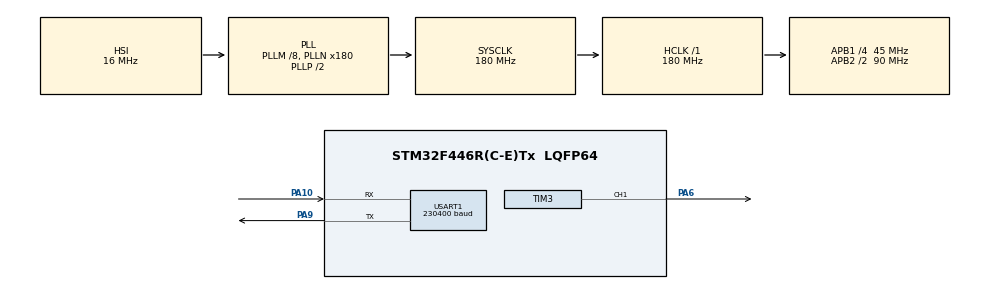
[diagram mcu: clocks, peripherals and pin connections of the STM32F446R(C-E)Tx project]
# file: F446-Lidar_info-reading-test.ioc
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Dma.Request0=USART1_RX
Dma.USART1_RX.0.Direction=DMA_PERIPH_TO_MEMORY
Dma.USART1_RX.0.FIFOMode=DMA_FIFOMODE_DISABLE
Dma.USART1_RX.0.Instance=DMA2_Stream2
Dma.USART1_RX.0.MemDataAlignment=DMA_MDATAALIGN_BYTE
Dma.USART1_RX.0.MemInc=DMA_MINC_ENABLE
Dma.USART1_RX.0.Mode=DMA_CIRCULAR
Dma.USART1_RX.0.PeriphDataAlignment=DMA_PDATAALIGN_BYTE
Dma.USART1_RX.0.PeriphInc=DMA_PINC_DISABLE
Dma.USART1_RX.0.Priority=DMA_PRIORITY_MEDIUM
Mcu.Family=STM32F4
Mcu.Name=STM32F446R(C-E)Tx
Mcu.Package=LQFP64
NVIC.DMA2_Stream2_IRQn=true\:0\:0\:false\:false\:true\:false\:true\:true
NVIC.PriorityGroup=NVIC_PRIORITYGROUP_4
PA10.Mode=Asynchronous
PA10.Signal=USART1_RX
PA6.Signal=S_TIM3_CH1
PA9.Mode=Asynchronous
PA9.Signal=USART1_TX
ProjectManager.HeapSize=0x200
ProjectManager.StackSize=0x400
ProjectManager.TargetToolchain=STM32CubeIDE
RCC.AHBFreq_Value=180000000
RCC.APB1CLKDivider=RCC_HCLK_DIV4
RCC.APB1Freq_Value=45000000
RCC.APB1TimFreq_Value=90000000
RCC.APB2CLKDivider=RCC_HCLK_DIV2
RCC.APB2Freq_Value=90000000
RCC.APB2TimFreq_Value=180000000
RCC.CortexFreq_Value=180000000
RCC.HCLKFreq_Value=180000000
RCC.PLLM=8
RCC.PLLN=180
RCC.SYSCLKFreq_VALUE=180000000
RCC.SYSCLKSource=RCC_SYSCLKSOURCE_PLLCLK
RCC.USBFreq_Value=180000000
RCC.VCOOutputFreq_Value=360000000
SH.S_TIM3_CH1.0=TIM3_CH1,PWM Generation1 CH1
TIM3.Channel-PWM\ Generation1\ CH1=TIM_CHANNEL_1
TIM3.Period=1000-1
TIM3.Prescaler=30-1
USART1.BaudRate=230400
USART1.VirtualMode=VM_ASYNC
board=custom

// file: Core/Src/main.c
/* USER CODE BEGIN Header */
/**
  ******************************************************************************
  * @file           : main.c
  * @brief          : Main program body
  ******************************************************************************
  * @attention
  *
  * Copyright (c) 2025 STMicroelectronics.
  * All rights reserved.
  *
  * This software is licensed under terms that can be found in the LICENSE file
  * in the root directory of this software component.
  * If no LICENSE file comes with this software, it is provided AS-IS.
  *
  ******************************************************************************
  */
/* USER CODE END Header */
#include "main.h"

/* USER CODE BEGIN Includes */
#include "mainpp.hpp"
/* USER CODE END Includes */

TIM_HandleTypeDef htim3;

UART_HandleTypeDef huart1;
DMA_HandleTypeDef hdma_usart1_rx;

void SystemClock_Config(void);
static void MX_GPIO_Init(void);
static void MX_DMA_Init(void);
static void MX_USART1_UART_Init(void);
static void MX_TIM3_Init(void);

int main(void)
{

  /* MCU Configuration--------------------------------------------------------*/

  /* Reset of all peripherals, Initializes the Flash interface and the Systick. */
  HAL_Init();

  /* Configure the system clock */
  SystemClock_Config();

  /* Initialize all configured peripherals */
  MX_GPIO_Init();
  MX_DMA_Init();
  MX_USART1_UART_Init();
  MX_TIM3_Init();
  /* USER CODE BEGIN 2 */
  main_function();
  /* USER CODE END 2 */

  /* Infinite loop */
  while (1)
  {

  }
}

void SystemClock_Config(void)
{
  RCC_OscInitTypeDef RCC_OscInitStruct = {0};
  RCC_ClkInitTypeDef RCC_ClkInitStruct = {0};

  /** Configure the main internal regulator output voltage
  */
  __HAL_RCC_PWR_CLK_ENABLE();
  __HAL_PWR_VOLTAGESCALING_CONFIG(PWR_REGULATOR_VOLTAGE_SCALE1);

  /** Initializes the RCC Oscillators according to the specified parameters
  * in the RCC_OscInitTypeDef structure.
  */
  RCC_OscInitStruct.OscillatorType = RCC_OSCILLATORTYPE_HSI;
  RCC_OscInitStruct.HSIState = RCC_HSI_ON;
  RCC_OscInitStruct.HSICalibrationValue = RCC_HSICALIBRATION_DEFAULT;
  RCC_OscInitStruct.PLL.PLLState = RCC_PLL_ON;
  RCC_OscInitStruct.PLL.PLLSource = RCC_PLLSOURCE_HSI;
  RCC_OscInitStruct.PLL.PLLM = 8;
  RCC_OscInitStruct.PLL.PLLN = 180;
  RCC_OscInitStruct.PLL.PLLP = RCC_PLLP_DIV2;
  RCC_OscInitStruct.PLL.PLLQ = 2;
  RCC_OscInitStruct.PLL.PLLR = 2;
  if (HAL_RCC_OscConfig(&RCC_OscInitStruct) != HAL_OK)
  {
    Error_Handler();
  }

  /** Activate the Over-Drive mode
  */
  if (HAL_PWREx_EnableOverDrive() != HAL_OK)
  {
    Error_Handler();
  }

  /** Initializes the CPU, AHB and APB buses clocks
  */
  RCC_ClkInitStruct.ClockType = RCC_CLOCKTYPE_HCLK|RCC_CLOCKTYPE_SYSCLK
                              |RCC_CLOCKTYPE_PCLK1|RCC_CLOCKTYPE_PCLK2;
  RCC_ClkInitStruct.SYSCLKSource = RCC_SYSCLKSOURCE_PLLCLK;
  RCC_ClkInitStruct.AHBCLKDivider = RCC_SYSCLK_DIV1;
  RCC_ClkInitStruct.APB1CLKDivider = RCC_HCLK_DIV4;
  RCC_ClkInitStruct.APB2CLKDivider = RCC_HCLK_DIV2;

  if (HAL_RCC_ClockConfig(&RCC_ClkInitStruct, FLASH_LATENCY_5) != HAL_OK)
  {
    Error_Handler();
  }
}

static void MX_TIM3_Init(void)
{

  TIM_MasterConfigTypeDef sMasterConfig = {0};
  TIM_OC_InitTypeDef sConfigOC = {0};

  htim3.Instance = TIM3;
  htim3.Init.Prescaler = 30-1;
  htim3.Init.CounterMode = TIM_COUNTERMODE_UP;
  htim3.Init.Period = 1000-1;
  htim3.Init.ClockDivision = TIM_CLOCKDIVISION_DIV1;
  htim3.Init.AutoReloadPreload = TIM_AUTORELOAD_PRELOAD_DISABLE;
  if (HAL_TIM_PWM_Init(&htim3) != HAL_OK)
  {
    Error_Handler();
  }
  sMasterConfig.MasterOutputTrigger = TIM_TRGO_RESET;
  sMasterConfig.MasterSlaveMode = TIM_MASTERSLAVEMODE_DISABLE;
  if (HAL_TIMEx_MasterConfigSynchronization(&htim3, &sMasterConfig) != HAL_OK)
  {
    Error_Handler();
  }
  sConfigOC.OCMode = TIM_OCMODE_PWM1;
  sConfigOC.Pulse = 0;
  sConfigOC.OCPolarity = TIM_OCPOLARITY_HIGH;
  sConfigOC.OCFastMode = TIM_OCFAST_DISABLE;
  if (HAL_TIM_PWM_ConfigChannel(&htim3, &sConfigOC, TIM_CHANNEL_1) != HAL_OK)
  {
    Error_Handler();
  }
  HAL_TIM_MspPostInit(&htim3);

}

static void MX_USART1_UART_Init(void)
{

  huart1.Instance = USART1;
  huart1.Init.BaudRate = 230400;
  huart1.Init.WordLength = UART_WORDLENGTH_8B;
  huart1.Init.StopBits = UART_STOPBITS_1;
  huart1.Init.Parity = UART_PARITY_NONE;
  huart1.Init.Mode = UART_MODE_TX_RX;
  huart1.Init.HwFlowCtl = UART_HWCONTROL_NONE;
  huart1.Init.OverSampling = UART_OVERSAMPLING_16;
  if (HAL_UART_Init(&huart1) != HAL_OK)
  {
    Error_Handler();
  }

}

static void MX_DMA_Init(void)
{

  /* DMA controller clock enable */
  __HAL_RCC_DMA2_CLK_ENABLE();

  /* DMA interrupt init */
  /* DMA2_Stream2_IRQn interrupt configuration */
  HAL_NVIC_SetPriority(DMA2_Stream2_IRQn, 0, 0);
  HAL_NVIC_EnableIRQ(DMA2_Stream2_IRQn);

}

static void MX_GPIO_Init(void)
{

  /* GPIO Ports Clock Enable */
  __HAL_RCC_GPIOA_CLK_ENABLE();

}

void Error_Handler(void)
{
  __disable_irq();
  while (1)
  {
  }
}
